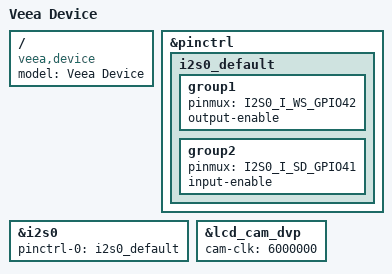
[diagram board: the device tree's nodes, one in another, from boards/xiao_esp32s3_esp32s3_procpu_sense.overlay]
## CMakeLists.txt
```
cmake_minimum_required(VERSION 3.20.0)

if(DEFINED BOARD AND BOARD STREQUAL "veea-device")
  set(BOARD "xiao_esp32s3/esp32s3/procpu/sense" CACHE STRING "" FORCE)
endif()

find_package(Zephyr REQUIRED HINTS $ENV{ZEPHYR_BASE})
project(veea_wearable)

# Override Zephyr's I2S ESP32 driver with our PDM-patched version.
# This replaces the upstream driver to add PDM RX support on I2S0
# without modifying the Zephyr tree.
if(CONFIG_I2S_ESP32_PDM_RX)
  get_target_property(i2s_sources drivers__i2s SOURCES)
  list(FILTER i2s_sources EXCLUDE REGEX "i2s_esp32\\.c$")
  set_target_properties(drivers__i2s PROPERTIES SOURCES "${i2s_sources}")
  target_sources(drivers__i2s PRIVATE ${CMAKE_CURRENT_SOURCE_DIR}/src/i2s_esp32_pdm.c)
endif()

target_sources(app PRIVATE
  src/main.c
  src/ble_audio_service.c
  src/mic_driver.c
)
```

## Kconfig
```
# Veea firmware Kconfig

config I2S_ESP32_PDM_RX
	bool "ESP32 I2S PDM RX mode on I2S0"
	depends on I2S_ESP32
	default n
	help
	  Enable PDM RX mode on I2S0 for PDM microphones (e.g. MSM261S4030H0R
	  on Xiao ESP32-S3 Sense expansion board).
	  ESP32-S3 only supports PDM-to-PCM converter on I2S0.
	  When enabled, the patched i2s_esp32_pdm.c replaces the upstream
	  Zephyr I2S driver for I2S0 to use PDM slot/clock configuration.

source "Kconfig.zephyr"
```

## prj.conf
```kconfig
CONFIG_SERIAL=y
CONFIG_UART_CONSOLE=y
CONFIG_PRINTK=y
CONFIG_LOG=y

CONFIG_BT=y
CONFIG_BT_PERIPHERAL=y
CONFIG_BT_DEVICE_NAME="the-tag"
CONFIG_BT_MAX_CONN=1
# Larger ATT MTU so photo notifications can carry 200-byte payloads.
# The phone will negotiate MTU on connection; we advertise up to 517 bytes.
CONFIG_BT_L2CAP_TX_MTU=517
CONFIG_BT_BUF_ACL_TX_SIZE=251
CONFIG_BT_BUF_ACL_RX_SIZE=251

# Camera + filesystem for image capture
CONFIG_VIDEO=y
CONFIG_I2C=y
CONFIG_VIDEO_I2C_RETRY_NUM=3
CONFIG_VIDEO_BUFFER_POOL_NUM_MAX=1
CONFIG_VIDEO_BUFFER_POOL_ALIGN=32
CONFIG_VIDEO_BUFFER_POOL_HEAP_SIZE=4096
CONFIG_SDHC=y
CONFIG_SPI_SDHC=y
CONFIG_DISK_ACCESS=y
CONFIG_DISK_DRIVERS=y
CONFIG_FILE_SYSTEM=y
CONFIG_FAT_FILESYSTEM_ELM=y
CONFIG_HEAP_MEM_POOL_SIZE=16384

# snprintf support for building numbered SD card filenames
CONFIG_CBPRINTF_FP_SUPPORT=n

# Use external PSRAM for large allocations (ESP32-S3 Sense has 8MB PSRAM)
CONFIG_ESP_SPIRAM=y
CONFIG_SPIRAM_MODE_OCT=y
CONFIG_SPIRAM_TYPE_ESPPSRAM64=y
CONFIG_ESP_SPIRAM_SIZE=8388608
CONFIG_SPIRAM_SPEED_80M=y
CONFIG_ESP_SPIRAM_HEAP_SIZE=5242880

# PSRAM heap allocation support
CONFIG_SHARED_MULTI_HEAP=y

# Camera DMA descriptors - need more for high resolution
CONFIG_DMA_ESP32_MAX_DESCRIPTOR_NUM=512

# Audio: I2S microphone + LC3 encoding for BLE audio streaming
CONFIG_I2S=y
CONFIG_I2S_ESP32_PDM_RX=y
CONFIG_FPU=y
CONFIG_LIBLC3=y
```

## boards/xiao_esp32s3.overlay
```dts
/ {
	model = "Veea Device";
	compatible = "veea,device";
};

&lcd_cam_dvp {
	cam-clk = <6000000>;
};
```

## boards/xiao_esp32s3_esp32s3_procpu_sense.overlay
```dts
/*
 * Veea Device overlay for Xiao ESP32-S3 Sense
 *
 * I2S0 is used for the built-in PDM microphone.
 * ESP32-S3 only supports PDM mode on I2S0 (not I2S1).
 *
 * Built-in PDM mic (MSM261S4030H0R) on Sense expansion board:
 *   GPIO42 → PDM CLK  (I2S0 WS output)
 *   GPIO41 → PDM DATA (I2S0 SD input)
 *
 * I2S0 and LCD_CAM share DMA resources, so mic is stopped during
 * camera capture (handled in main.c).
 */

#include <zephyr/dt-bindings/pinctrl/esp-pinctrl-common.h>
#include <zephyr/dt-bindings/pinctrl/esp32s3-pinctrl.h>
#include <zephyr/dt-bindings/pinctrl/esp32s3-gpio-sigmap.h>

/ {
	model = "Veea Device";
	compatible = "veea,device";
};

&pinctrl {
	i2s0_default: i2s0_default {
		group1 {
			pinmux = <I2S0_I_WS_GPIO42>;
			output-enable;
		};
		group2 {
			pinmux = <I2S0_I_SD_GPIO41>;
			input-enable;
		};
	};
};

&i2s0 {
	status = "okay";
	pinctrl-0 = <&i2s0_default>;
	pinctrl-names = "default";
};

&lcd_cam_dvp {
	cam-clk = <6000000>;
};
```

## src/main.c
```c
#include <zephyr/kernel.h>
#include <zephyr/sys/printk.h>

#include <zephyr/bluetooth/bluetooth.h>
#include <zephyr/bluetooth/hci.h>
#include <zephyr/bluetooth/conn.h>
#include <zephyr/bluetooth/gatt.h>
#include <zephyr/bluetooth/uuid.h>
#include <zephyr/device.h>
#include <zephyr/drivers/video.h>
#include <zephyr/drivers/i2c.h>
#include <zephyr/fs/fs.h>
#include <zephyr/storage/disk_access.h>
#include <zephyr/multi_heap/shared_multi_heap.h>
#include <ff.h>

#include "ble_audio_service.h"
#include "mic_driver.h"

/* ---- Storage ---- */
#define DISK_DRIVE_NAME "SD"
#define DISK_MOUNT_PT   "/SD:"

/* ---- Capture timing ---- */
#define CAPTURE_INTERVAL_MS  30000   /* one picture every 30 s              */
#define BLE_PHOTO_CHUNK_SIZE 200     /* bytes of photo data per notify      */

/*
 * BLE service / characteristic UUIDs – identical to the omiGlass firmware so
 * the same mobile app can be used without modification.
 *
 * Service:       19B10000-E8F2-537E-4F6C-D104768A1214
 * Photo data:    19B10005-E8F2-537E-4F6C-D104768A1214
 */
#define OMI_SVC_UUID \
	BT_UUID_DECLARE_128(BT_UUID_128_ENCODE(0x19B10000, 0xE8F2, 0x537E, \
					       0x4F6C, 0xD104768A1214))
#define PHOTO_DATA_UUID \
	BT_UUID_DECLARE_128(BT_UUID_128_ENCODE(0x19B10005, 0xE8F2, 0x537E, \
					       0x4F6C, 0xD104768A1214))

/* ------------------------------------------------------------------
 * BLE – connection state and GATT service
 * ------------------------------------------------------------------
 *
 * Static GATT service attribute layout:
 *   [0] Primary service declaration
 *   [1] Characteristic declaration
 *   [2] Characteristic value  <-- target for bt_gatt_notify()
 *   [3] CCC descriptor
 */
#define PHOTO_DATA_ATTR_IDX 2

static struct bt_conn *ble_conn;
static bool           ble_connected;
static bool           photo_notify_enabled;

static void photo_ccc_changed(const struct bt_gatt_attr *attr, uint16_t value)
{
	photo_notify_enabled = (value == BT_GATT_CCC_NOTIFY);
	printk("Photo notify %s\n", photo_notify_enabled ? "enabled" : "disabled");
}

BT_GATT_SERVICE_DEFINE(veea_svc,
	BT_GATT_PRIMARY_SERVICE(OMI_SVC_UUID),
	BT_GATT_CHARACTERISTIC(PHOTO_DATA_UUID, BT_GATT_CHRC_NOTIFY,
			       BT_GATT_PERM_NONE, NULL, NULL, NULL),
	BT_GATT_CCC(photo_ccc_changed,
		    BT_GATT_PERM_READ | BT_GATT_PERM_WRITE),
);

/* Advertise the service UUID so phones can filter by it */
static const struct bt_data ad[] = {
	BT_DATA_BYTES(BT_DATA_FLAGS, (BT_LE_AD_GENERAL | BT_LE_AD_NO_BREDR)),
	BT_DATA_BYTES(BT_DATA_UUID128_ALL,
		      BT_UUID_128_ENCODE(0x19B10000, 0xE8F2, 0x537E,
					 0x4F6C, 0xD104768A1214)),
};

static const struct bt_data sd[] = {
	BT_DATA(BT_DATA_NAME_COMPLETE, CONFIG_BT_DEVICE_NAME,
		(sizeof(CONFIG_BT_DEVICE_NAME) - 1)),
};

static void connected_cb(struct bt_conn *conn, uint8_t err)
{
	if (err) {
		printk("Connection failed (err %u)\n", err);
		return;
	}
	ble_conn      = bt_conn_ref(conn);
	ble_connected = true;
	printk("BLE connected\n");
}

static void disconnected_cb(struct bt_conn *conn, uint8_t reason)
{
	printk("BLE disconnected (reason %u)\n", reason);
	ble_connected        = false;
	photo_notify_enabled = false;
	if (ble_conn) {
		bt_conn_unref(ble_conn);
		ble_conn = NULL;
	}
}

BT_CONN_CB_DEFINE(conn_callbacks) = {
	.connected    = connected_cb,
	.disconnected = disconnected_cb,
};

/* ------------------------------------------------------------------
 * SD card
 * ------------------------------------------------------------------*/
static FATFS fat_fs;
static struct fs_mount_t sd_mount = {
	.type      = FS_FATFS,
	.fs_data   = &fat_fs,
	.mnt_point = DISK_MOUNT_PT,
};
static bool sd_mounted;

/* ------------------------------------------------------------------
 * OV2640 camera sensor
 * ------------------------------------------------------------------*/
static const struct device *ov2640_i2c_bus;

static int ov2640_write_reg(const struct device *i2c, uint8_t reg, uint8_t val)
{
	uint8_t buf[2] = { reg, val };
	return i2c_write(i2c, buf, 2, 0x30);
}

static const uint8_t ov2640_default_regs[][2] = {
	{0xFF, 0x00}, /* BANK_SEL = DSP */
	{0x2c, 0xff},
	{0x2e, 0xdf},
	{0xFF, 0x01}, /* BANK_SEL = sensor */
	{0x3c, 0x32},
	{0x11, 0x00}, /* CLKRC - no clock divider */
	{0x09, 0x02}, /* COM2 - output drive 3x */
	{0x04, 0x28 | 0x08}, /* REG04 */
	{0x13, 0xE7}, /* COM8 - enable AGC, AEC, AWB, banding filter */
	{0x14, 0x08 | (0x07 << 5)}, /* COM9 - AGC gain ceiling 128x (max) */
	{0x15, 0x00}, /* COM10 */
	{0x2D, 0x00}, /* AEC LSB */
	{0x2E, 0x00}, /* AEC MSB */
	{0x45, 0x7F}, /* AECHH - AEC high bits (max exposure time) */
	{0x10, 0xFF}, /* AEC[7:0] - longer exposure */
	{0x2c, 0x0c},
	{0x33, 0x78},
	{0x3a, 0x33},
	{0x3b, 0xfb},
	{0x3e, 0x00},
	{0x43, 0x11},
	{0x16, 0x10},
	{0x39, 0x02},
	{0x35, 0x88},
	{0x22, 0x0a},
	{0x37, 0x40},
	{0x23, 0x00},
	{0x34, 0xa0}, /* ARCOM2 */
	{0x06, 0x02},
	{0x06, 0x88},
	{0x07, 0xc0},
	{0x0d, 0xb7},
	{0x0e, 0x01},
	{0x4c, 0x00},
	{0x4a, 0x81},
	{0x21, 0x99},
	{0x24, 0xA0}, /* AEW - target brightness (very high) */
	{0x25, 0x90}, /* AEB - floor brightness (very high) */
	{0x26, 0xD6}, /* VV - AEC/AGC thresholds */
	{0x48, 0x00}, /* COM19 */
	{0x49, 0x00}, /* ZOOMS */
	{0x5c, 0x00},
	{0x63, 0x00},
	{0x46, 0x00}, /* FLL */
	{0x47, 0x00}, /* FLH */
	{0x0C, 0x38 | 0x02}, /* COM3 */
	{0x5D, 0x55},
	{0x5E, 0x7d},
	{0x5F, 0x7d},
	{0x60, 0x55},
	{0x61, 0x70}, /* HISTO_LOW */
	{0x62, 0x80}, /* HISTO_HIGH */
	{0x7c, 0x05},
	{0x20, 0x80},
	{0x28, 0x30},
	{0x6c, 0x00},
	{0x6d, 0x80},
	{0x6e, 0x00},
	{0x70, 0x02},
	{0x71, 0x94},
	{0x73, 0xc1},
	{0x3d, 0x34},
	{0x5a, 0x57},
	{0x4F, 0xbb}, /* BD50 */
	{0x50, 0x9c}, /* BD60 */
	{0xFF, 0x00}, /* BANK_SEL = DSP */
	{0xe5, 0x7f},
	{0xF9, 0x80 | 0x40}, /* MC_BIST */
	{0x41, 0x24},
	{0xE0, 0x10 | 0x04}, /* RESET */
	{0x76, 0xff},
	{0x33, 0xa0},
	{0x42, 0x20},
	{0x43, 0x18},
	{0x4c, 0x00},
	{0x87, 0x80 | 0x40 | 0x10}, /* CTRL3 */
	{0x88, 0x3f},
	{0xd7, 0x03},
	{0xd9, 0x10},
	{0xD3, 0x80 | 0x02}, /* R_DVP_SP */
	{0xc8, 0x08},
	{0xc9, 0x80},
	{0x7c, 0x00},
	{0x7d, 0x00},
	{0x7c, 0x03},
	{0x7d, 0x48},
	{0x7d, 0x48},
	{0x7c, 0x08},
	{0x7d, 0x20},
	{0x7d, 0x10},
	{0x7d, 0x0e},
	{0x90, 0x00},
	{0x91, 0x0e},
	{0x91, 0x1a},
	{0x91, 0x31},
	{0x91, 0x5a},
	{0x91, 0x69},
	{0x91, 0x75},
	{0x91, 0x7e},
	{0x91, 0x88},
	{0x91, 0x8f},
	{0x91, 0x96},
	{0x91, 0xa3},
	{0x91, 0xaf},
	{0x91, 0xc4},
	{0x91, 0xd7},
	{0x91, 0xe8},
	{0x91, 0x20},
	{0xC2, 0x0C}, /* CTRL0 - RGB565 mode */
};

/* JPEG output format – applied after video_set_format(JPEG)
 * QS = 0x10 gives medium-high quality (equivalent to ~quality 50 in
 * Arduino esp_camera terms); lower value = larger file / better quality.
 */
static const uint8_t ov2640_jpeg_regs[][2] = {
	{0xFF, 0x01}, /* BANK_SEL = sensor */
	{0x11, 0x01}, /* CLKRC /2 for JPEG stability */
	{0xFF, 0x00}, /* BANK_SEL = DSP */
	{0xDA, 0x10}, /* IMAGE_MODE – JPEG output */
	{0xD7, 0x03},
	{0xE0, 0x00}, /* RESET – normal operation */
	{0x44, 0x10}, /* QS – JPEG quantization scale */
};

/* RGB565 output format – force OV2640 to output true RGB565 */
static const uint8_t ov2640_rgb565_regs[][2] = {
	{0xFF, 0x00}, /* BANK_SEL = DSP */
	{0xDA, 0x08}, /* IMAGE_MODE – RGB565 output */
	{0xD7, 0x03},
	{0xDF, 0x00},
	{0x33, 0xa0},
	{0x3C, 0x00},
	{0xe1, 0x67},
	{0xC2, 0x0C}, /* CTRL0 – RGB565 mode (not YUV) */
	{0xE0, 0x00}, /* RESET – normal operation */
};

static int ov2640_init_sensor(const struct device *i2c)
{
	int ret;
	size_t i;

	printk("Initializing OV2640 sensor...\n");

	/* Soft reset */
	ret = ov2640_write_reg(i2c, 0xFF, 0x01);
	if (ret) return ret;
	ret = ov2640_write_reg(i2c, 0x12, 0x80);
	if (ret) return ret;
	k_sleep(K_MSEC(100));

	/* Write default registers (exposure, gain settings) */
	for (i = 0; i < ARRAY_SIZE(ov2640_default_regs); i++) {
		ret = ov2640_write_reg(i2c, ov2640_default_regs[i][0],
				       ov2640_default_regs[i][1]);
		if (ret) {
			printk("Failed to write default reg 0x%02x (%d)\n",
			       ov2640_default_regs[i][0], ret);
			return ret;
		}
	}

	/* Output format registers are applied per-capture via ov2640_jpeg_regs
	 * or ov2640_rgb565_regs after video_set_format() is called.
	 */
	printk("OV2640 initialization complete, waiting for AEC...\n");
	k_sleep(K_MSEC(500));
	return 0;
}

static bool ov2640_detected_on_bus(const struct device *i2c, const char *bus_name)
{
	uint8_t buf[2];
	uint8_t pid = 0;
	uint8_t ver = 0;
	int ret;

	if (!device_is_ready(i2c)) {
		printk("%s not ready\n", bus_name);
		return false;
	}

	/* Wait for camera to power up */
	k_sleep(K_MSEC(100));

	/* Select sensor register bank (0xFF = 0x01) */
	buf[0] = 0xFF;
	buf[1] = 0x01;
	ret = i2c_write(i2c, buf, 2, 0x30);
	if (ret != 0) {
		printk("%s OV2640 bank select failed (%d)\n", bus_name, ret);
		return false;
	}

	k_sleep(K_MSEC(10));

	/* Read PID register (0x0A) */
	buf[0] = 0x0A;
	ret = i2c_write_read(i2c, 0x30, buf, 1, &pid, 1);
	if (ret != 0) {
		printk("%s OV2640 PID read failed (%d)\n", bus_name, ret);
		return false;
	}

	/* Read VER register (0x0B) */
	buf[0] = 0x0B;
	ret = i2c_write_read(i2c, 0x30, buf, 1, &ver, 1);
	if (ret != 0) {
		printk("%s OV2640 VER read failed (%d)\n", bus_name, ret);
		return false;
	}

	if ((pid == 0x00 && ver == 0x00) || (pid == 0xFF && ver == 0xFF)) {
		printk("%s OV2640 invalid ID (PID 0x%02x VER 0x%02x)\n",
		       bus_name, pid, ver);
		return false;
	}

	printk("%s OV2640 detected (PID 0x%02x VER 0x%02x)\n", bus_name, pid, ver);

	/* Initialize the camera since Zephyr driver failed at boot */
	ret = ov2640_init_sensor(i2c);
	if (ret != 0) {
		printk("OV2640 init failed (%d)\n", ret);
		return false;
	}

	ov2640_i2c_bus = i2c;
	return true;
}

static bool ov2640_detected(void)
{
	const struct device *i2c1 = DEVICE_DT_GET(DT_NODELABEL(i2c1));
	const struct device *i2c0 = DEVICE_DT_GET(DT_NODELABEL(i2c0));

	if (ov2640_detected_on_bus(i2c1, "I2C1")) {
		return true;
	}
	if (ov2640_detected_on_bus(i2c0, "I2C0")) {
		printk("OV2640 responds on I2C0; update devicetree if needed.\n");
		return true;
	}
	return false;
}

static int mount_sdcard(void)
{
	int ret;

	if (sd_mounted) {
		return 0;
	}

	ret = disk_access_ioctl(DISK_DRIVE_NAME, DISK_IOCTL_CTRL_INIT, NULL);
	if (ret != 0) {
		printk("SD init failed (%d)\n", ret);
		return ret;
	}

	ret = fs_mount(&sd_mount);
	if (ret < 0) {
		printk("SD mount failed (%d)\n", ret);
		return ret;
	}

	sd_mounted = true;
	return 0;
}

static int fs_write_all(struct fs_file_t *file, const uint8_t *data, size_t len)
{
	size_t offset = 0;

	while (offset < len) {
		ssize_t wrote = fs_write(file, data + offset, len - offset);
		if (wrote < 0) {
			return (int)wrote;
		}
		offset += (size_t)wrote;
	}
	return 0;
}

/* Write RGB565 frame as a 24-bit BMP (fallback when JPEG is unavailable) */
static int bmp_write_rgb565(struct fs_file_t *file, const uint8_t *rgb565,
			    uint32_t width, uint32_t height, uint32_t pitch)
{
	uint8_t header[54];
	uint32_t row_size = ((width * 3 + 3) / 4) * 4; /* 24-bit, 4-byte row align */
	uint32_t pixel_data_size = row_size * height;
	uint32_t file_size = 54 + pixel_data_size;
	uint8_t *row_buf;
	int ret;

	row_buf = shared_multi_heap_alloc(SMH_REG_ATTR_EXTERNAL, row_size);
	if (!row_buf) {
		row_buf = k_malloc(row_size);
	}
	if (!row_buf) {
		printk("BMP: no memory for row buffer (%u bytes)\n", row_size);
		return -ENOMEM;
	}

	memset(header, 0, sizeof(header));
	/* BMP file header */
	header[0] = 'B'; header[1] = 'M';
	header[2] = file_size & 0xFF;
	header[3] = (file_size >> 8) & 0xFF;
	header[4] = (file_size >> 16) & 0xFF;
	header[5] = (file_size >> 24) & 0xFF;
	header[10] = 54; /* pixel data offset */
	/* DIB header (BITMAPINFOHEADER) */
	header[14] = 40;
	header[18] = width & 0xFF;
	header[19] = (width >> 8) & 0xFF;
	header[20] = (width >> 16) & 0xFF;
	header[21] = (width >> 24) & 0xFF;
	header[22] = height & 0xFF;
	header[23] = (height >> 8) & 0xFF;
	header[24] = (height >> 16) & 0xFF;
	header[25] = (height >> 24) & 0xFF;
	header[26] = 1;   /* colour planes */
	header[28] = 24;  /* bits per pixel */
	header[34] = pixel_data_size & 0xFF;
	header[35] = (pixel_data_size >> 8) & 0xFF;
	header[36] = (pixel_data_size >> 16) & 0xFF;
	header[37] = (pixel_data_size >> 24) & 0xFF;

	ret = fs_write_all(file, header, sizeof(header));
	if (ret != 0) {
		shared_multi_heap_free(row_buf);
		return ret;
	}

	/* BMP rows are stored bottom-to-top */
	for (int32_t y = height - 1; y >= 0; y--) {
		const uint8_t *src = rgb565 + y * pitch;

		memset(row_buf, 0, row_size);
		for (uint32_t x = 0; x < width; x++) {
			/* ESP32 DVP outputs RGB565 big-endian */
			uint16_t px = ((uint16_t)src[2 * x] << 8) | src[2 * x + 1];
			uint8_t r = (px >> 11) & 0x1F;
			uint8_t g = (px >> 5)  & 0x3F;
			uint8_t b =  px        & 0x1F;

			/* Expand to 8-bit; store as BGR for BMP */
			row_buf[x * 3 + 0] = (b << 3) | (b >> 2);
			row_buf[x * 3 + 1] = (g << 2) | (g >> 4);
			row_buf[x * 3 + 2] = (r << 3) | (r >> 2);
		}

		ret = fs_write_all(file, row_buf, row_size);
		if (ret != 0) {
			shared_multi_heap_free(row_buf);
			return ret;
		}
	}

	shared_multi_heap_free(row_buf);
	printk("BMP: wrote %ux%u image (%u bytes)\n", width, height, file_size);
	return 0;
}

/* ------------------------------------------------------------------
 * BLE photo streaming
 *
 * Protocol (compatible with omiGlass mobile app):
 *   First chunk:      [idx_lo, idx_hi, orientation, data…]  (≤203 bytes)
 *   Subsequent:       [idx_lo, idx_hi, data…]               (≤202 bytes)
 *   End-of-photo:     [0xFF, 0xFF]
 * ------------------------------------------------------------------*/
static int stream_photo_ble(const uint8_t *data, size_t len)
{
	static uint8_t chunk[BLE_PHOTO_CHUNK_SIZE + 3];
	uint16_t frame_idx = 0;
	size_t offset = 0;
	int ret;

	printk("BLE stream: %u bytes\n", len);

	while (offset < len) {
		size_t remaining = len - offset;
		size_t copy_len;
		size_t chunk_len;

		if (frame_idx == 0) {
			/* First chunk carries an orientation byte */
			copy_len  = MIN(remaining, BLE_PHOTO_CHUNK_SIZE - 1U);
			chunk[0]  = 0;    /* frame index low */
			chunk[1]  = 0;    /* frame index high */
			chunk[2]  = 0;    /* orientation: 0° */
			memcpy(&chunk[3], data + offset, copy_len);
			chunk_len = copy_len + 3;
		} else {
			copy_len  = MIN(remaining, BLE_PHOTO_CHUNK_SIZE);
			chunk[0]  = (uint8_t)(frame_idx & 0xFF);
			chunk[1]  = (uint8_t)((frame_idx >> 8) & 0xFF);
			memcpy(&chunk[2], data + offset, copy_len);
			chunk_len = copy_len + 2;
		}

		ret = bt_gatt_notify(NULL, &veea_svc.attrs[PHOTO_DATA_ATTR_IDX],
				     chunk, (uint16_t)chunk_len);
		if (ret != 0) {
			printk("BLE notify failed (%d)\n", ret);
			return ret;
		}

		offset    += copy_len;
		frame_idx++;
		k_sleep(K_MSEC(5)); /* yield so BLE stack can flush */
	}

	/* End-of-photo marker */
	chunk[0] = 0xFF;
	chunk[1] = 0xFF;
	ret = bt_gatt_notify(NULL, &veea_svc.attrs[PHOTO_DATA_ATTR_IDX], chunk, 2);
	if (ret != 0) {
		printk("BLE end-marker notify failed (%d)\n", ret);
	}

	printk("BLE stream complete: %u chunks sent\n", frame_idx);
	return 0;
}

/* ------------------------------------------------------------------
 * capture_and_route – capture one frame and either stream it over
 * BLE (when connected with notifications enabled) or save it to the
 * SD card (numbered IMG%05u.JPG / IMG%05u.BMP).
 * ------------------------------------------------------------------*/
static uint32_t image_counter;
static bool camera_initialized;

static int capture_and_route(void)
{
	const struct device *camera = DEVICE_DT_GET(DT_CHOSEN(zephyr_camera));
	struct video_format fmt = { 0 };
	struct video_buffer *dequeued = NULL;
	struct video_buffer *buffers[CONFIG_VIDEO_BUFFER_POOL_NUM_MAX] = { 0 };
	uint8_t buffer_count = 0;
	bool streaming = false;
	int ret;

	if (!device_is_ready(camera)) {
		printk("Camera device not ready\n");
		return -ENODEV;
	}

	/* Initialize camera sensor only once */
	if (!camera_initialized) {
		if (!ov2640_detected()) {
			printk("Camera not detected on I2C\n");
			return -ENODEV;
		}
		camera_initialized = true;
		k_sleep(K_MSEC(200));
	}

	/*
	 * Force RGB565 – Zephyr ESP32-S3 DVP driver does not produce valid
	 * JPEG output (bytesused is always 0).  We capture RGB565 and let
	 * the mobile app convert to a displayable image.
	 *
	 * Use 320x240 (QVGA) as a good balance between quality and BLE
	 * transfer time.  160x120 is too small; 640x480 is 600 KB which
	 * takes ~60 s over BLE at 200 bytes/chunk.
	 */
	uint32_t width  = 320;
	uint32_t height = 240;

	printk("Capturing RGB565 %ux%u...\n", width, height);

	fmt.type        = VIDEO_BUF_TYPE_OUTPUT;
	fmt.pixelformat = VIDEO_PIX_FMT_RGB565;
	fmt.width       = width;
	fmt.height      = height;
	fmt.pitch       = width * 2;

	ret = video_set_format(camera, &fmt);
	if (ret != 0) {
		printk("Set format failed (%d)\n", ret);
		return ret;
	}

	/* Apply RGB565 OV2640 registers after video_set_format() */
	if (ov2640_i2c_bus) {
		for (size_t i = 0; i < ARRAY_SIZE(ov2640_rgb565_regs); i++) {
			ov2640_write_reg(ov2640_i2c_bus,
					 ov2640_rgb565_regs[i][0],
					 ov2640_rgb565_regs[i][1]);
		}
	}

	/* Use actual format returned by driver */
	width  = fmt.width;
	height = fmt.height;

	if (fmt.size == 0) {
		fmt.size = width * height * 2U;
	}

	uint32_t pitch = fmt.pitch ? fmt.pitch : (width * 2U);

	struct video_caps caps = { .type = VIDEO_BUF_TYPE_OUTPUT };
	ret = video_get_caps(camera, &caps);
	buffer_count = (ret == 0 && caps.min_vbuf_count) ? caps.min_vbuf_count : 1U;
	if (buffer_count > ARRAY_SIZE(buffers)) {
		buffer_count = ARRAY_SIZE(buffers);
	}

	for (uint8_t i = 0; i < buffer_count; i++) {
		size_t total = sizeof(struct video_buffer) + fmt.size
			       + CONFIG_VIDEO_BUFFER_POOL_ALIGN;
		uint8_t *mem = shared_multi_heap_alloc(SMH_REG_ATTR_EXTERNAL,
						       total);
		if (!mem) {
			mem = k_malloc(total);
		}
		if (!mem) {
			printk("No frame buffer memory (%u bytes)\n",
			       (unsigned)total);
			ret = -ENOMEM;
			goto cleanup;
		}

		buffers[i] = (struct video_buffer *)mem;
		memset(buffers[i], 0, sizeof(struct video_buffer));

		uintptr_t da = (uintptr_t)(mem + sizeof(struct video_buffer));
		da = (da + CONFIG_VIDEO_BUFFER_POOL_ALIGN - 1)
		     & ~(uintptr_t)(CONFIG_VIDEO_BUFFER_POOL_ALIGN - 1);
		buffers[i]->buffer = (uint8_t *)da;
		buffers[i]->size   = fmt.size;
		buffers[i]->type   = VIDEO_BUF_TYPE_OUTPUT;

		ret = video_enqueue(camera, buffers[i]);
		if (ret != 0) {
			printk("Enqueue failed (%d)\n", ret);
			goto cleanup;
		}
	}

	ret = video_stream_start(camera, VIDEO_BUF_TYPE_OUTPUT);
	if (ret != 0) {
		printk("Stream start failed (%d)\n", ret);
		goto cleanup;
	}
	streaming = true;

	/* Allow auto-exposure to settle */
	printk("Waiting for AEC to settle...\n");
	k_sleep(K_MSEC(2000));

	ret = video_dequeue(camera, &dequeued, K_SECONDS(10));
	video_stream_stop(camera, VIDEO_BUF_TYPE_OUTPUT);
	streaming = false;

	if (ret != 0 || dequeued == NULL) {
		printk("No frame received (%d)\n", ret);
		ret = ret ? ret : -EIO;
		goto cleanup;
	}

	/* Validate we got actual data */
	size_t img_len = dequeued->bytesused;
	if (img_len == 0) {
		/* bytesused=0 means driver didn't report size; use expected size */
		img_len = width * height * 2U;
		printk("Warning: bytesused=0, using expected size %u\n",
		       (unsigned)img_len);
	}

	/* Refine pitch from actual bytes transferred */
	if (dequeued->bytesused) {
		uint32_t computed = dequeued->bytesused / height;
		if (computed && computed != pitch) {
			printk("Pitch adjusted %u -> %u\n", pitch, computed);
			pitch = computed;
		}
	}

	printk("Frame captured: %u bytes (RGB565 %ux%u)\n",
	       (unsigned)img_len, width, height);

	/* Log first 16 bytes for debugging */
	printk("First 16 bytes:");
	for (int i = 0; i < 16 && i < (int)img_len; i++) {
		printk(" %02x", dequeued->buffer[i]);
	}
	printk("\n");

	/* ---------------------------------------------------------------
	 * Route: BLE when connected with notifications enabled,
	 *        otherwise SD card.
	 * ---------------------------------------------------------------*/
	if (ble_connected && photo_notify_enabled) {
		printk("Streaming image over BLE...\n");
		ret = stream_photo_ble(dequeued->buffer, img_len);
	} else {
		char path[32];

		snprintf(path, sizeof(path), DISK_MOUNT_PT "/IMG%05u.BMP",
			 (unsigned)image_counter);

		ret = mount_sdcard();
		if (ret != 0) {
			printk("SD unavailable – image dropped\n");
			ret = 0; /* non-fatal */
			goto cleanup;
		}

		struct fs_file_t file;
		fs_file_t_init(&file);
		ret = fs_open(&file, path, FS_O_CREATE | FS_O_WRITE | FS_O_TRUNC);
		if (ret != 0) {
			printk("Open %s failed (%d)\n", path, ret);
			goto cleanup;
		}

		ret = bmp_write_rgb565(&file, dequeued->buffer,
				       width, height, pitch);
		fs_close(&file);

		if (ret != 0) {
			printk("Write to %s failed (%d)\n", path, ret);
			goto cleanup;
		}

		printk("Saved %s\n", path);
		image_counter++;
	}

	ret = 0;

cleanup:
	if (streaming) {
		video_stream_stop(camera, VIDEO_BUF_TYPE_OUTPUT);
	}
	for (uint8_t i = 0; i < buffer_count; i++) {
		if (buffers[i]) {
			shared_multi_heap_free(buffers[i]);
		}
	}
	return ret;
}

/* ------------------------------------------------------------------
 * Main
 * ------------------------------------------------------------------*/
int main(void)
{
	int err;
	struct bt_le_adv_param adv_params = BT_LE_ADV_PARAM_INIT(
		BT_LE_ADV_OPT_CONN,
		BT_GAP_ADV_FAST_INT_MIN_2,
		BT_GAP_ADV_FAST_INT_MAX_2,
		NULL);

	printk("Veea wearable device starting...\n");

	err = bt_enable(NULL);
	if (err) {
		printk("Bluetooth init failed (err %d)\n", err);
		return 0;
	}

	err = bt_le_adv_start(&adv_params, ad, ARRAY_SIZE(ad), sd, ARRAY_SIZE(sd));
	if (err) {
		printk("Advertising failed (err %d)\n", err);
		return 0;
	}

	printk("BLE advertising started\n");
	printk("Continuous capture every %d ms – BLE streams when connected, "
	       "SD card otherwise\n", CAPTURE_INTERVAL_MS);

	/* Initialise audio subsystem */
	ble_audio_service_init();
	int mic_err = mic_driver_init();
	if (mic_err) {
		printk("Mic driver init failed (%d) – audio disabled\n", mic_err);
	} else {
		printk("Audio subsystem ready\n");
	}

	while (true) {
		/* Pause mic during camera capture to avoid DMA contention */
		bool mic_was_running = mic_driver_is_running();
		if (mic_was_running) {
			mic_driver_stop();
		}

		int ret = capture_and_route();

		if (mic_was_running) {
			mic_driver_start();
		}

		if (ret != 0) {
			printk("Capture error (%d), retrying next cycle\n", ret);
		}
		k_sleep(K_MSEC(CAPTURE_INTERVAL_MS));
	}

	return 0;
}
```

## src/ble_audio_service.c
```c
#include <zephyr/kernel.h>
#include <zephyr/bluetooth/bluetooth.h>
#include <zephyr/bluetooth/gatt.h>
#include <zephyr/bluetooth/uuid.h>
#include <zephyr/sys/printk.h>
#include <string.h>

#include "ble_audio_service.h"
#include "mic_driver.h"

static struct bt_uuid_128 audio_svc_uuid =
	BT_UUID_INIT_128(BT_UUID_128_ENCODE(0x19B10000, 0xE8F2, 0x537E,
					     0x4F6C, 0xD104768A1214));
static struct bt_uuid_128 audio_data_uuid =
	BT_UUID_INIT_128(BLE_AUDIO_DATA_CHAR_UUID);
static struct bt_uuid_128 audio_ctrl_uuid =
	BT_UUID_INIT_128(BLE_AUDIO_CTRL_CHAR_UUID);

static bool data_notify_enabled;
static bool ctrl_notify_enabled;

/* Forward declarations */
static void data_ccc_changed(const struct bt_gatt_attr *attr, uint16_t value);
static void ctrl_ccc_changed(const struct bt_gatt_attr *attr, uint16_t value);
static ssize_t ctrl_write_cb(struct bt_conn *conn,
			     const struct bt_gatt_attr *attr,
			     const void *buf, uint16_t len,
			     uint16_t offset, uint8_t flags);

/*
 * GATT service – must be defined before any function references attrs[].
 *   [0] Primary service
 *   [1] Audio Data char decl
 *   [2] Audio Data char value  ← notify frames
 *   [3] Audio Data CCC
 *   [4] Audio Ctrl char decl
 *   [5] Audio Ctrl char value  ← notify status / write commands
 *   [6] Audio Ctrl CCC
 */
BT_GATT_SERVICE_DEFINE(veea_audio_svc,
	BT_GATT_PRIMARY_SERVICE(&audio_svc_uuid),

	BT_GATT_CHARACTERISTIC(&audio_data_uuid.uuid,
			       BT_GATT_CHRC_NOTIFY,
			       BT_GATT_PERM_NONE,
			       NULL, NULL, NULL),
	BT_GATT_CCC(data_ccc_changed,
		     BT_GATT_PERM_READ | BT_GATT_PERM_WRITE),

	BT_GATT_CHARACTERISTIC(&audio_ctrl_uuid.uuid,
			       BT_GATT_CHRC_WRITE | BT_GATT_CHRC_NOTIFY,
			       BT_GATT_PERM_WRITE,
			       NULL, ctrl_write_cb, NULL),
	BT_GATT_CCC(ctrl_ccc_changed,
		     BT_GATT_PERM_READ | BT_GATT_PERM_WRITE),
);

static void data_ccc_changed(const struct bt_gatt_attr *attr, uint16_t value)
{
	data_notify_enabled = (value == BT_GATT_CCC_NOTIFY);
	printk("Audio data notify %s\n",
	       data_notify_enabled ? "enabled" : "disabled");
}

static void ctrl_ccc_changed(const struct bt_gatt_attr *attr, uint16_t value)
{
	ctrl_notify_enabled = (value == BT_GATT_CCC_NOTIFY);
	printk("Audio ctrl notify %s\n",
	       ctrl_notify_enabled ? "enabled" : "disabled");
}

static void send_ctrl_status(uint8_t status)
{
	if (!ctrl_notify_enabled) {
		return;
	}
	const struct bt_gatt_attr *attr = &veea_audio_svc.attrs[5];
	bt_gatt_notify(NULL, attr, &status, sizeof(status));
}

static ssize_t ctrl_write_cb(struct bt_conn *conn,
			     const struct bt_gatt_attr *attr,
			     const void *buf, uint16_t len,
			     uint16_t offset, uint8_t flags)
{
	ARG_UNUSED(conn);
	ARG_UNUSED(attr);
	ARG_UNUSED(offset);
	ARG_UNUSED(flags);

	const uint8_t *cmd = buf;
	if (len < 1) {
		return BT_GATT_ERR(BT_ATT_ERR_INVALID_ATTRIBUTE_LEN);
	}

	switch (cmd[0]) {
	case AUDIO_CMD_START:
		printk("Audio CMD_START\n");
		mic_driver_start();
		send_ctrl_status(AUDIO_STATUS_RECORDING);
		break;
	case AUDIO_CMD_STOP:
		printk("Audio CMD_STOP\n");
		mic_driver_stop();
		send_ctrl_status(AUDIO_STATUS_STOPPED);
		break;
	default:
		printk("Unknown audio cmd: 0x%02x\n", cmd[0]);
		return BT_GATT_ERR(BT_ATT_ERR_NOT_SUPPORTED);
	}
	return len;
}

void ble_audio_service_notify_frame(const uint8_t *lc3_data, uint16_t len,
				    uint16_t seq)
{
	if (!data_notify_enabled) {
		return;
	}
	if (len > AUDIO_FRAME_BYTES) {
		len = AUDIO_FRAME_BYTES;
	}

	uint8_t frame[AUDIO_FRAME_HEADER_SIZE + AUDIO_FRAME_BYTES];
	frame[0] = (uint8_t)(seq & 0xFF);
	frame[1] = (uint8_t)((seq >> 8) & 0xFF);
	frame[2] = (uint8_t)(len & 0xFF);
	frame[3] = (uint8_t)((len >> 8) & 0xFF);
	memcpy(&frame[AUDIO_FRAME_HEADER_SIZE], lc3_data, len);

	const struct bt_gatt_attr *attr = &veea_audio_svc.attrs[2];
	bt_gatt_notify(NULL, attr, frame, AUDIO_FRAME_HEADER_SIZE + len);
}

bool ble_audio_service_is_streaming(void)
{
	return data_notify_enabled;
}

void ble_audio_service_init(void)
{
	data_notify_enabled = false;
	ctrl_notify_enabled = false;
	printk("BLE Audio Service initialised\n");
}
```

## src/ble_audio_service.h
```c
#ifndef BLE_AUDIO_SERVICE_H
#define BLE_AUDIO_SERVICE_H

#include <zephyr/types.h>
#include <stdbool.h>

/* LC3 audio parameters */
#define AUDIO_SAMPLE_RATE_HZ        16000
#define AUDIO_FRAME_DURATION_US     10000   /* 10 ms */
#define AUDIO_BITRATE_BPS           32000   /* 32 kbps */
#define AUDIO_FRAME_BYTES           40      /* 32000 / 8 * 0.010 = 40 bytes per LC3 frame */
#define AUDIO_CHANNELS              1       /* Mono */
#define AUDIO_PCM_SAMPLES_PER_FRAME 160     /* 16000 Hz * 0.010 s */

/*
 * BLE Audio UUIDs – under the omiGlass service (19B10000-...)
 * Audio Data:    19B10001-E8F2-537E-4F6C-D104768A1214
 * Audio Control: 19B10002-E8F2-537E-4F6C-D104768A1214
 */
#define BLE_AUDIO_DATA_CHAR_UUID \
	BT_UUID_128_ENCODE(0x19B10001, 0xE8F2, 0x537E, 0x4F6C, 0xD104768A1214)

#define BLE_AUDIO_CTRL_CHAR_UUID \
	BT_UUID_128_ENCODE(0x19B10002, 0xE8F2, 0x537E, 0x4F6C, 0xD104768A1214)

/* Control commands (phone → firmware) */
#define AUDIO_CMD_START  0x01
#define AUDIO_CMD_STOP   0x02

/* Status notifications (firmware → phone) */
#define AUDIO_STATUS_RECORDING  0x01
#define AUDIO_STATUS_STOPPED    0x02
#define AUDIO_STATUS_ERROR      0xFF

/* Frame header: [seq_lo, seq_hi, len_lo, len_hi, ...LC3 data...] */
#define AUDIO_FRAME_HEADER_SIZE 4

void ble_audio_service_init(void);
void ble_audio_service_notify_frame(const uint8_t *lc3_data, uint16_t len,
				    uint16_t seq);
bool ble_audio_service_is_streaming(void);

#endif /* BLE_AUDIO_SERVICE_H */
```

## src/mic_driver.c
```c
 #include <zephyr/kernel.h>
#include <zephyr/drivers/i2s.h>
#include <zephyr/sys/printk.h>
#include <zephyr/device.h>
#include <zephyr/devicetree.h>
#include <lc3.h>
#include <string.h>

#include "mic_driver.h"
#include "ble_audio_service.h"

/* ------------------------------------------------------------------ */
/* Constants                                                            */
/* ------------------------------------------------------------------ */

#define MIC_PCM_SAMPLES    AUDIO_PCM_SAMPLES_PER_FRAME /* 160 mono samples */
#define MIC_I2S_CHANNELS   2  /* ESP32 I2S driver requires stereo */
#define MIC_I2S_BUF_BYTES  (MIC_PCM_SAMPLES * MIC_I2S_CHANNELS * sizeof(int16_t))
#define MIC_FRAMES_PER_BUF 2  /* PDM mono: 320 samples = 2 × 160-sample LC3 frames */
#define MIC_SLAB_BLOCKS    8
#define MIC_THREAD_STACK   4096
#define MIC_FRAME_LOG_INTERVAL 100

/* ------------------------------------------------------------------ */
/* Static storage                                                       */
/* ------------------------------------------------------------------ */

K_MEM_SLAB_DEFINE_STATIC(mic_slab, MIC_I2S_BUF_BYTES, MIC_SLAB_BLOCKS, 4);

static const struct device *i2s_dev;
static volatile bool running;
static bool i2s_hw_ready;
static uint16_t frame_seq;

/* LC3 encoder */
static lc3_encoder_t lc3_enc;
static lc3_encoder_mem_16k_t lc3_enc_mem;
static uint8_t lc3_out[AUDIO_FRAME_BYTES];

/* Capture thread */
static struct k_thread mic_thread;
K_THREAD_STACK_DEFINE(mic_stack, MIC_THREAD_STACK);

/* ------------------------------------------------------------------ */
/* I2S RX configuration                                                 */
/* ------------------------------------------------------------------ */

static int i2s_configure_rx(void)
{
	struct i2s_config cfg = {
		.word_size      = 16,
		.channels       = MIC_I2S_CHANNELS,
		.format         = I2S_FMT_DATA_FORMAT_I2S,
		.options        = I2S_OPT_FRAME_CLK_MASTER |
				  I2S_OPT_BIT_CLK_MASTER,
		.frame_clk_freq = AUDIO_SAMPLE_RATE_HZ,
		.block_size     = MIC_I2S_BUF_BYTES,
		.mem_slab       = &mic_slab,
		.timeout        = 2000,
	};

	return i2s_configure(i2s_dev, I2S_DIR_RX, &cfg);
}

/* ------------------------------------------------------------------ */
/* Lazy I2S hardware init                                               */
/* ------------------------------------------------------------------ */

static int i2s_hw_init(void)
{
	if (i2s_hw_ready) {
		return 0;
	}

	i2s_dev = DEVICE_DT_GET(DT_NODELABEL(i2s0));
	if (!device_is_ready(i2s_dev)) {
		printk("I2S0 device not ready\n");
		i2s_dev = NULL;
		return -ENODEV;
	}

	i2s_hw_ready = true;
	printk("I2S0 hardware ready\n");
	return 0;
}

/* ------------------------------------------------------------------ */
/* Capture thread                                                       */
/* ------------------------------------------------------------------ */

static void mic_capture_fn(void *p1, void *p2, void *p3)
{
	ARG_UNUSED(p1);
	ARG_UNUSED(p2);
	ARG_UNUSED(p3);

	printk("Mic capture thread started\n");
	int eio_count = 0;

	while (running) {
		void *pcm_buf;
		size_t pcm_size;

		int err = i2s_read(i2s_dev, &pcm_buf, &pcm_size);
		if (err) {
			if (err == -EIO) {
				eio_count++;
				if (eio_count >= 3) {
					printk("I2S EIO - recovering\n");
					i2s_trigger(i2s_dev, I2S_DIR_RX,
						    I2S_TRIGGER_PREPARE);
					i2s_configure_rx();
					i2s_trigger(i2s_dev, I2S_DIR_RX,
						    I2S_TRIGGER_START);
					eio_count = 0;
				}
				k_msleep(5);
				continue;
			}
			if (err != -EAGAIN) {
				printk("I2S read error: %d\n", err);
			}
			k_msleep(1);
			continue;
		}

		eio_count = 0;

		if (pcm_size < MIC_I2S_BUF_BYTES) {
			k_mem_slab_free(&mic_slab, pcm_buf);
			continue;
		}

		/* PDM mono mode outputs 320 sequential mono samples in the
		 * 640-byte "stereo" buffer (not interleaved L/R pairs).
		 * Encode as 2 LC3 frames of 160 samples each.
		 */
		int16_t *samples = (int16_t *)pcm_buf;
		int total_samples = pcm_size / sizeof(int16_t);

		for (int f = 0; f < MIC_FRAMES_PER_BUF; f++) {
			int16_t *frame_pcm = &samples[f * MIC_PCM_SAMPLES];

			uint16_t seq = frame_seq++;

			if ((seq % MIC_FRAME_LOG_INTERVAL) == 0U) {
				printk("PCM[%u]: %d %d %d %d %d %d %d %d\n",
				       seq, frame_pcm[0], frame_pcm[1],
				       frame_pcm[2], frame_pcm[3],
				       frame_pcm[4], frame_pcm[5],
				       frame_pcm[6], frame_pcm[7]);
			}

			int enc_err = lc3_encode(lc3_enc, LC3_PCM_FORMAT_S16,
					 frame_pcm, 1,
					 AUDIO_FRAME_BYTES, lc3_out);

			if (enc_err) {
				printk("LC3 encode error: %d\n", enc_err);
				continue;
			}

			ble_audio_service_notify_frame(lc3_out, AUDIO_FRAME_BYTES, seq);

			if ((seq % MIC_FRAME_LOG_INTERVAL) == 0U) {
				printk("Audio frame %u sent\n", seq);
			}
		}

		k_mem_slab_free(&mic_slab, pcm_buf);
	}

	printk("Mic capture thread stopped\n");
}

/* ------------------------------------------------------------------ */
/* Public API                                                           */
/* ------------------------------------------------------------------ */

int mic_driver_init(void)
{
	i2s_dev = NULL;
	i2s_hw_ready = false;

	lc3_enc = lc3_setup_encoder(AUDIO_FRAME_DURATION_US,
				    AUDIO_SAMPLE_RATE_HZ,
				    AUDIO_SAMPLE_RATE_HZ,
				    &lc3_enc_mem);
	if (!lc3_enc) {
		printk("LC3 encoder init failed\n");
		return -ENOMEM;
	}

	running = false;
	frame_seq = 0;
	printk("Mic driver init OK (LC3 ready, I2S0 PDM deferred)\n");
	return 0;
}

void mic_driver_start(void)
{
	if (running) {
		return;
	}

	int err = i2s_hw_init();
	if (err) {
		printk("Mic: I2S0 init failed (%d)\n", err);
		return;
	}

	err = i2s_configure_rx();
	if (err) {
		printk("I2S configure failed: %d\n", err);
		return;
	}

	err = i2s_trigger(i2s_dev, I2S_DIR_RX, I2S_TRIGGER_START);
	if (err) {
		printk("I2S start failed: %d\n", err);
		return;
	}

	running = true;
	frame_seq = 0;

	k_thread_create(&mic_thread, mic_stack,
			K_THREAD_STACK_SIZEOF(mic_stack),
			mic_capture_fn, NULL, NULL, NULL,
			K_PRIO_PREEMPT(2), 0, K_NO_WAIT);
	k_thread_name_set(&mic_thread, "mic_capture");

	printk("Microphone started (I2S0 PDM)\n");
}

void mic_driver_stop(void)
{
	if (!running) {
		return;
	}

	running = false;
	i2s_trigger(i2s_dev, I2S_DIR_RX, I2S_TRIGGER_STOP);
	k_thread_join(&mic_thread, K_SECONDS(2));
	printk("Microphone stopped\n");
}

bool mic_driver_is_running(void)
{
	return running;
}
```

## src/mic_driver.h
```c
#ifndef MIC_DRIVER_H
#define MIC_DRIVER_H

#include <zephyr/types.h>
#include <stdbool.h>

int mic_driver_init(void);
void mic_driver_start(void);
void mic_driver_stop(void);
bool mic_driver_is_running(void);

#endif /* MIC_DRIVER_H */
```
